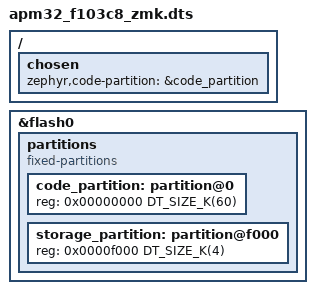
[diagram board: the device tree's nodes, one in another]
/*
 * Copyright (c) 2024 APM68 Keyboard
 *
 * SPDX-License-Identifier: MIT
 */

#include "apm32_f103c8.dts"

/ {
	chosen {
		zephyr,code-partition = &code_partition;
	};
};

&flash0 {
	partitions {
		compatible = "fixed-partitions";
		#address-cells = <1>;
		#size-cells = <1>;

		/* Application code partition: 60KB */
		code_partition: partition@0 {
			reg = <0x00000000 DT_SIZE_K(60)>;
		};

		/* Storage partition for ZMK settings: 4KB */
		storage_partition: partition@f000 {
			reg = <0x0000f000 DT_SIZE_K(4)>;
		};
	};
};
